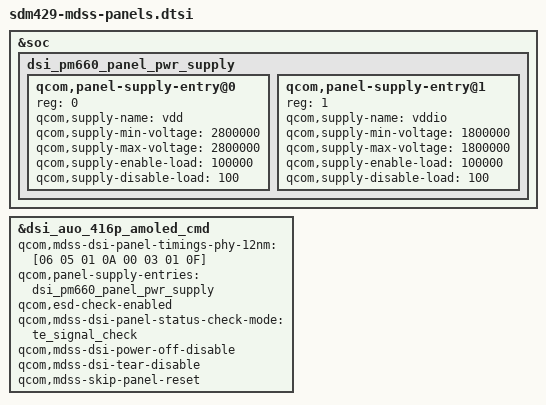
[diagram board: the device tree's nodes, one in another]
/* Copyright (c) 2020, The Linux Foundation. All rights reserved.
 *
 * This program is free software; you can redistribute it and/or modify
 * it under the terms of the GNU General Public License version 2 and
 * only version 2 as published by the Free Software Foundation.
 *
 * This program is distributed in the hope that it will be useful,
 * but WITHOUT ANY WARRANTY; without even the implied warranty of
 * MERCHANTABILITY or FITNESS FOR A PARTICULAR PURPOSE.  See the
 * GNU General Public License for more details.
 */

#include "dsi-panel-auo-416p-amoled-cmd.dtsi"

&soc {
	dsi_pm660_panel_pwr_supply: dsi_pm660_panel_pwr_supply {
		#address-cells = <1>;
		#size-cells = <0>;

		qcom,panel-supply-entry@0 {
			reg = <0>;
			qcom,supply-name = "vdd";
			qcom,supply-min-voltage = <2800000>;
			qcom,supply-max-voltage = <2800000>;
			qcom,supply-enable-load = <100000>;
			qcom,supply-disable-load = <100>;
		};

		qcom,panel-supply-entry@1 {
			reg = <1>;
			qcom,supply-name = "vddio";
			qcom,supply-min-voltage = <1800000>;
			qcom,supply-max-voltage = <1800000>;
			qcom,supply-enable-load = <100000>;
			qcom,supply-disable-load = <100>;
		};
	};
};

&dsi_auo_416p_amoled_cmd {
	/delete-property/ qcom,mdss-dsi-panel-timings;
	qcom,mdss-dsi-panel-timings-phy-12nm = [06 05 01 0A 00 03 01 0F];
	qcom,panel-supply-entries = <&dsi_pm660_panel_pwr_supply>;
	qcom,esd-check-enabled;
	qcom,mdss-dsi-panel-status-check-mode = "te_signal_check";
	qcom,mdss-dsi-power-off-disable;
	qcom,mdss-dsi-tear-disable;
	qcom,mdss-skip-panel-reset;
};


